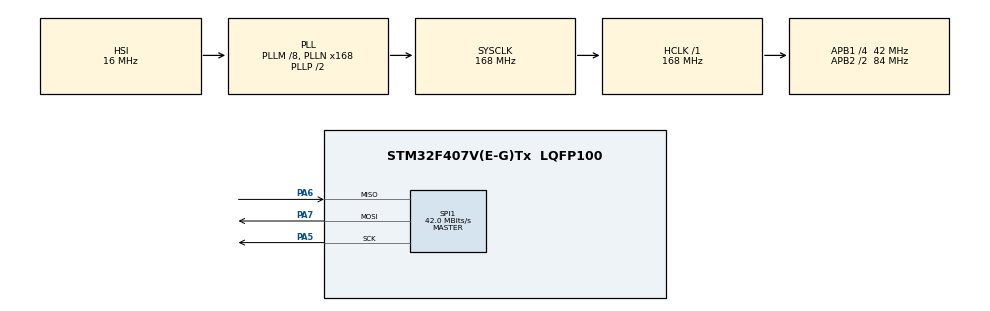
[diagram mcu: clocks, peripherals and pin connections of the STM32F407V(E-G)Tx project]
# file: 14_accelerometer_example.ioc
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Mcu.Family=STM32F4
Mcu.Name=STM32F407V(E-G)Tx
Mcu.Package=LQFP100
NVIC.PriorityGroup=NVIC_PRIORITYGROUP_4
PA13.Mode=Serial_Wire
PA13.Signal=SYS_JTMS-SWDIO
PA14.Mode=Serial_Wire
PA14.Signal=SYS_JTCK-SWCLK
PA5.Mode=Full_Duplex_Master
PA5.Signal=SPI1_SCK
PA6.Mode=Full_Duplex_Master
PA6.Signal=SPI1_MISO
PA7.Mode=Full_Duplex_Master
PA7.Signal=SPI1_MOSI
ProjectManager.HeapSize=0x200
ProjectManager.StackSize=0x400
ProjectManager.TargetToolchain=MDK-ARM V5
RCC.48MHZClocksFreq_Value=84000000
RCC.AHBFreq_Value=168000000
RCC.APB1CLKDivider=RCC_HCLK_DIV4
RCC.APB1Freq_Value=42000000
RCC.APB1TimFreq_Value=84000000
RCC.APB2CLKDivider=RCC_HCLK_DIV2
RCC.APB2Freq_Value=84000000
RCC.APB2TimFreq_Value=168000000
RCC.CortexFreq_Value=168000000
RCC.HCLKFreq_Value=168000000
RCC.HSE_VALUE=25000000
RCC.HSI_VALUE=16000000
RCC.LSE_VALUE=32768
RCC.PLLM=8
RCC.PLLN=168
RCC.SYSCLKFreq_VALUE=168000000
RCC.SYSCLKSource=RCC_SYSCLKSOURCE_PLLCLK
RCC.VCOOutputFreq_Value=336000000
SPI1.CalculateBaudRate=42.0 MBits/s
SPI1.Direction=SPI_DIRECTION_2LINES
SPI1.Mode=SPI_MODE_MASTER
SPI1.VirtualType=VM_MASTER
board=14_accelerometer_example

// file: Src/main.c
/**
  ******************************************************************************
  * File Name          : main.c
  * Description        : Main program body
  ******************************************************************************
  ** This notice applies to any and all portions of this file
  * that are not between comment pairs USER CODE BEGIN and
  * USER CODE END. Other portions of this file, whether
  * inserted by the user or by software development tools
  * are owned by their respective copyright owners.
  *
  * COPYRIGHT(c) 2018 STMicroelectronics
  *
  * Redistribution and use in source and binary forms, with or without modification,
  * are permitted provided that the following conditions are met:
  *   1. Redistributions of source code must retain the above copyright notice,
  *      this list of conditions and the following disclaimer.
  *   2. Redistributions in binary form must reproduce the above copyright notice,
  *      this list of conditions and the following disclaimer in the documentation
  *      and/or other materials provided with the distribution.
  *   3. Neither the name of STMicroelectronics nor the names of its contributors
  *      may be used to endorse or promote products derived from this software
  *      without specific prior written permission.
  *
  * THIS SOFTWARE IS PROVIDED BY THE COPYRIGHT HOLDERS AND CONTRIBUTORS "AS IS"
  * AND ANY EXPRESS OR IMPLIED WARRANTIES, INCLUDING, BUT NOT LIMITED TO, THE
  * IMPLIED WARRANTIES OF MERCHANTABILITY AND FITNESS FOR A PARTICULAR PURPOSE ARE
  * DISCLAIMED. IN NO EVENT SHALL THE COPYRIGHT HOLDER OR CONTRIBUTORS BE LIABLE
  * FOR ANY DIRECT, INDIRECT, INCIDENTAL, SPECIAL, EXEMPLARY, OR CONSEQUENTIAL
  * DAMAGES (INCLUDING, BUT NOT LIMITED TO, PROCUREMENT OF SUBSTITUTE GOODS OR
  * SERVICES; LOSS OF USE, DATA, OR PROFITS; OR BUSINESS INTERRUPTION) HOWEVER
  * CAUSED AND ON ANY THEORY OF LIABILITY, WHETHER IN CONTRACT, STRICT LIABILITY,
  * OR TORT (INCLUDING NEGLIGENCE OR OTHERWISE) ARISING IN ANY WAY OUT OF THE USE
  * OF THIS SOFTWARE, EVEN IF ADVISED OF THE POSSIBILITY OF SUCH DAMAGE.
  *
  ******************************************************************************
  */
#include "main.h"
#include "stm32f4xx_hal.h"
// Tm nin sayfada kodlar mevcut ordan eklendi.............
#include "defines.h"
#include "tm_stm32_disco.h"
#include "tm_stm32_delay.h"
#include "tm_stm32_lis302dl_lis3dsh.h"

SPI_HandleTypeDef hspi1;

/* USER CODE BEGIN PV */
/* Private variables ---------------------------------------------------------*/

/* USER CODE END PV */

void SystemClock_Config(void);
static void MX_GPIO_Init(void);
static void MX_SPI1_Init(void);

/* USER CODE BEGIN PFP */
/* Private function prototypes -----------------------------------------------*/

/* USER CODE END PFP */

int main(void)
{

  /* MCU Configuration----------------------------------------------------------*/

  /* Reset of all peripherals, Initializes the Flash interface and the Systick. */
  HAL_Init();

  /* Configure the system clock */
  SystemClock_Config();

  /* Initialize all configured peripherals */
  MX_GPIO_Init();
  MX_SPI1_Init();

  /* USER CODE BEGIN 2 */
    TM_LIS302DL_LIS3DSH_t Axes_Data;

    /* Initialize system */
    SystemInit();

    /* Init delay */
    TM_DELAY_Init();

    /* Initialize LEDs */
    TM_DISCO_LedInit();

    /* Detect proper device */
    if (TM_LIS302DL_LIS3DSH_Detect() == TM_LIS302DL_LIS3DSH_Device_LIS302DL) {
        /* Turn on GREEN and RED */
        TM_DISCO_LedOn(LED_GREEN | LED_RED);
        /* Initialize LIS302DL */
        TM_LIS302DL_LIS3DSH_Init(TM_LIS302DL_Sensitivity_2_3G, TM_LIS302DL_Filter_2Hz);
    } else if (TM_LIS302DL_LIS3DSH_Detect() == TM_LIS302DL_LIS3DSH_Device_LIS3DSH) {
        /* Turn on BLUE and ORANGE */
        TM_DISCO_LedOn(LED_BLUE | LED_ORANGE);
        /* Initialize LIS3DSH */
        TM_LIS302DL_LIS3DSH_Init(TM_LIS3DSH_Sensitivity_2G, TM_LIS3DSH_Filter_800Hz);
    } else {
        /* Device is not recognized */

        /* Turn on ALL leds */
        TM_DISCO_LedOn(LED_GREEN | LED_RED | LED_BLUE | LED_ORANGE);

        /* Infinite loop */
        while (1);
  /* USER CODE END 2 */
}
  /* Infinite loop */
  while (1)
  {
  /* Read axes data from initialized accelerometer */
        TM_LIS302DL_LIS3DSH_ReadAxes(&Axes_Data);

        /* Turn LEDS on or off */
        /* Check X axes */
        if (Axes_Data.X > 200) {
            TM_DISCO_LedOn(LED_RED);
        } else {
            TM_DISCO_LedOff(LED_RED);
        }
        if (Axes_Data.X < -200) {
            TM_DISCO_LedOn(LED_GREEN);
        } else {
            TM_DISCO_LedOff(LED_GREEN);
        }
        /* Check Y axes */
        if (Axes_Data.Y > 200) {
            TM_DISCO_LedOn(LED_ORANGE);
        } else {
            TM_DISCO_LedOff(LED_ORANGE);
        }
        if (Axes_Data.Y < -200) {
            TM_DISCO_LedOn(LED_BLUE);
        } else {
            TM_DISCO_LedOff(LED_BLUE);
        }
  }

}

/** System Clock Configuration
*/
void SystemClock_Config(void)
{

  RCC_OscInitTypeDef RCC_OscInitStruct;
  RCC_ClkInitTypeDef RCC_ClkInitStruct;

    /**Configure the main internal regulator output voltage
    */
  __HAL_RCC_PWR_CLK_ENABLE();

  __HAL_PWR_VOLTAGESCALING_CONFIG(PWR_REGULATOR_VOLTAGE_SCALE1);

    /**Initializes the CPU, AHB and APB busses clocks
    */
  RCC_OscInitStruct.OscillatorType = RCC_OSCILLATORTYPE_HSI;
  RCC_OscInitStruct.HSIState = RCC_HSI_ON;
  RCC_OscInitStruct.HSICalibrationValue = 16;
  RCC_OscInitStruct.PLL.PLLState = RCC_PLL_ON;
  RCC_OscInitStruct.PLL.PLLSource = RCC_PLLSOURCE_HSI;
  RCC_OscInitStruct.PLL.PLLM = 8;
  RCC_OscInitStruct.PLL.PLLN = 168;
  RCC_OscInitStruct.PLL.PLLP = RCC_PLLP_DIV2;
  RCC_OscInitStruct.PLL.PLLQ = 4;
  if (HAL_RCC_OscConfig(&RCC_OscInitStruct) != HAL_OK)
  {
    _Error_Handler(__FILE__, __LINE__);
  }

    /**Initializes the CPU, AHB and APB busses clocks
    */
  RCC_ClkInitStruct.ClockType = RCC_CLOCKTYPE_HCLK|RCC_CLOCKTYPE_SYSCLK
                              |RCC_CLOCKTYPE_PCLK1|RCC_CLOCKTYPE_PCLK2;
  RCC_ClkInitStruct.SYSCLKSource = RCC_SYSCLKSOURCE_PLLCLK;
  RCC_ClkInitStruct.AHBCLKDivider = RCC_SYSCLK_DIV1;
  RCC_ClkInitStruct.APB1CLKDivider = RCC_HCLK_DIV4;
  RCC_ClkInitStruct.APB2CLKDivider = RCC_HCLK_DIV2;

  if (HAL_RCC_ClockConfig(&RCC_ClkInitStruct, FLASH_LATENCY_5) != HAL_OK)
  {
    _Error_Handler(__FILE__, __LINE__);
  }

    /**Configure the Systick interrupt time
    */
  HAL_SYSTICK_Config(HAL_RCC_GetHCLKFreq()/1000);

    /**Configure the Systick
    */
  HAL_SYSTICK_CLKSourceConfig(SYSTICK_CLKSOURCE_HCLK);

  /* SysTick_IRQn interrupt configuration */
  HAL_NVIC_SetPriority(SysTick_IRQn, 0, 0);
}

/* SPI1 init function */
static void MX_SPI1_Init(void)
{

  /* SPI1 parameter configuration*/
  hspi1.Instance = SPI1;
  hspi1.Init.Mode = SPI_MODE_MASTER;
  hspi1.Init.Direction = SPI_DIRECTION_2LINES;
  hspi1.Init.DataSize = SPI_DATASIZE_8BIT;
  hspi1.Init.CLKPolarity = SPI_POLARITY_LOW;
  hspi1.Init.CLKPhase = SPI_PHASE_1EDGE;
  hspi1.Init.NSS = SPI_NSS_SOFT;
  hspi1.Init.BaudRatePrescaler = SPI_BAUDRATEPRESCALER_2;
  hspi1.Init.FirstBit = SPI_FIRSTBIT_MSB;
  hspi1.Init.TIMode = SPI_TIMODE_DISABLE;
  hspi1.Init.CRCCalculation = SPI_CRCCALCULATION_DISABLE;
  hspi1.Init.CRCPolynomial = 10;
  if (HAL_SPI_Init(&hspi1) != HAL_OK)
  {
    _Error_Handler(__FILE__, __LINE__);
  }

}

/** Configure pins as
        * Analog
        * Input
        * Output
        * EVENT_OUT
        * EXTI
*/
static void MX_GPIO_Init(void)
{

  /* GPIO Ports Clock Enable */
  __HAL_RCC_GPIOA_CLK_ENABLE();

}

void _Error_Handler(char * file, int line)
{
  while(1)
  {
  }
}

/************************ (C) COPYRIGHT STMicroelectronics *****END OF FILE****/
